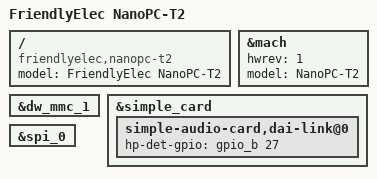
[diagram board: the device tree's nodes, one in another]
/*
 * (C) Copyright 2017 FriendlyElec Computer Tech. Co., Ltd.
 * (http://www.friendlyarm.com)
 *
 * This program is free software; you can redistribute it and/or
 * modify it under the terms of the GNU General Public License
 * as published by the Free Software Foundation; either version 2
 * of the License, or (at your option) any later version.
 *
 * This program is distributed in the hope that it will be useful,
 * but WITHOUT ANY WARRANTY; without even the implied warranty of
 * MERCHANTABILITY or FITNESS FOR A PARTICULAR PURPOSE.  See the
 * GNU General Public License for more details.
 *
 * You should have received a copy of the GNU General Public License
 * along with this program.  If not, see <http://www.gnu.org/licenses/>.
 */

/dts-v1/;
#include "s5p4418-nanopi2-common.dtsi"

/ {
	model = "FriendlyElec NanoPC-T2";
	compatible = "friendlyelec,nanopc-t2", "nexell,s5p4418";
};

&mach {
	hwrev = <1>;
	model = "NanoPC-T2";
};

&dw_mmc_1 {
	status = "okay";
};

&simple_card {
	simple-audio-card,dai-link@0 {
		hp-det-gpio = <&gpio_b 27 0>;
	};
};

&spi_0 {
	/delete-node/ fbtft@0;
};
